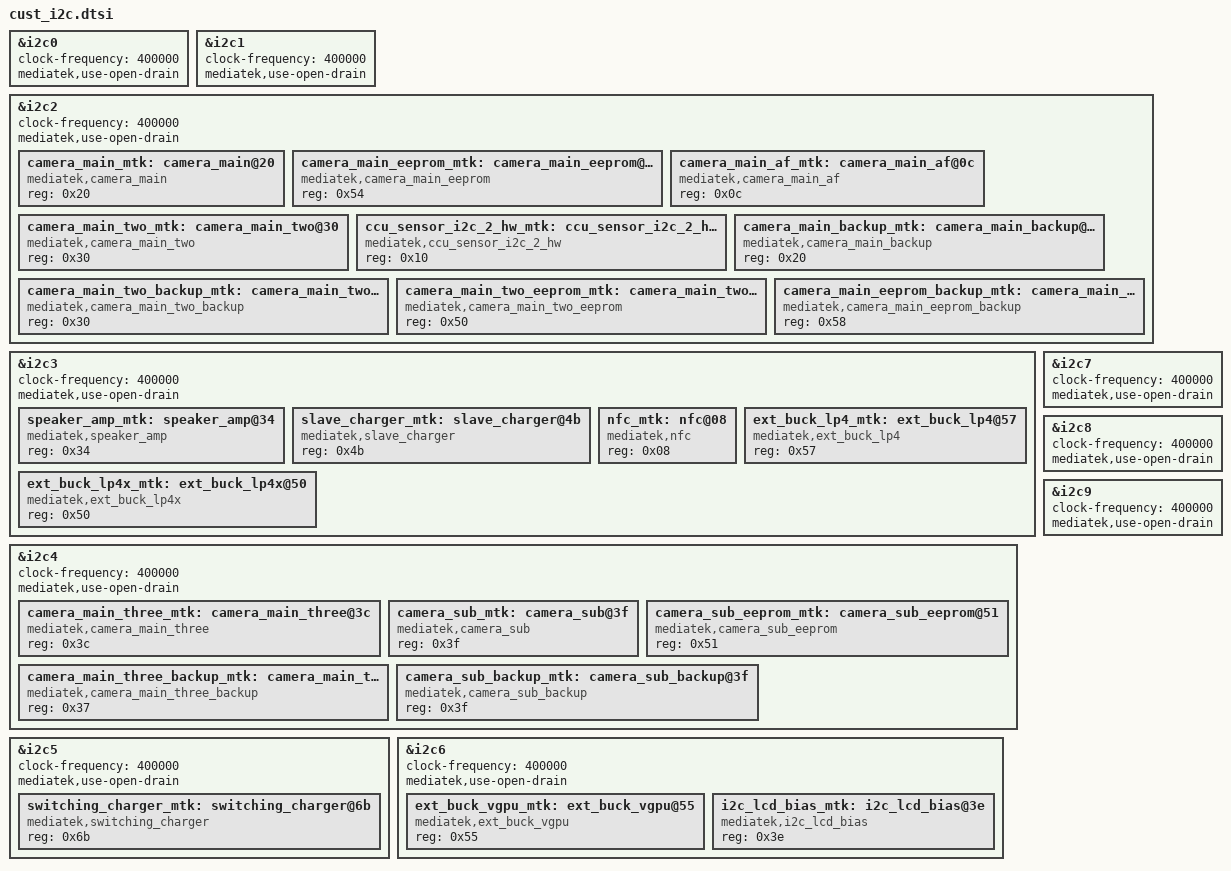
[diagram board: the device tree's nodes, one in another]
/*
 * Generated by MTK SP DrvGen Version: 3.5.160809 for MT6765.
 * 2023-08-23 20:59:31
 * Do Not Modify The File.
 * Copyright Mediatek Inc. (c) 2016.
*/

/*************************
 * I2C DTSI File
*************************/

&i2c0 {
	#address-cells = <1>;
	#size-cells = <0>;
	clock-frequency = <400000>;
	mediatek,use-open-drain;
};

&i2c1 {
	#address-cells = <1>;
	#size-cells = <0>;
	clock-frequency = <400000>;
	mediatek,use-open-drain;
};

&i2c2 {
	#address-cells = <1>;
	#size-cells = <0>;
	clock-frequency = <400000>;
	mediatek,use-open-drain;
	camera_main_mtk:camera_main@20 {
		compatible = "mediatek,camera_main";
		reg = <0x20>;
		status = "okay";
	};

	camera_main_eeprom_mtk:camera_main_eeprom@54 {
		compatible = "mediatek,camera_main_eeprom";
		reg = <0x54>;
		status = "okay";
	};

	camera_main_af_mtk:camera_main_af@0c {
		compatible = "mediatek,camera_main_af";
		reg = <0x0c>;
		status = "okay";
	};

	camera_main_two_mtk:camera_main_two@30 {
		compatible = "mediatek,camera_main_two";
		reg = <0x30>;
		status = "okay";
	};

	ccu_sensor_i2c_2_hw_mtk:ccu_sensor_i2c_2_hw@10 {
		compatible = "mediatek,ccu_sensor_i2c_2_hw";
		reg = <0x10>;
		status = "okay";
	};

	camera_main_backup_mtk:camera_main_backup@20 {
		compatible = "mediatek,camera_main_backup";
		reg = <0x20>;
		status = "okay";
	};

	camera_main_two_backup_mtk:camera_main_two_backup@30 {
		compatible = "mediatek,camera_main_two_backup";
		reg = <0x30>;
		status = "okay";
	};

	camera_main_two_eeprom_mtk:camera_main_two_eeprom@50 {
		compatible = "mediatek,camera_main_two_eeprom";
		reg = <0x50>;
		status = "okay";
	};

	camera_main_eeprom_backup_mtk:camera_main_eeprom_backup@58 {
		compatible = "mediatek,camera_main_eeprom_backup";
		reg = <0x58>;
		status = "okay";
	};

};

&i2c3 {
	#address-cells = <1>;
	#size-cells = <0>;
	clock-frequency = <400000>;
	mediatek,use-open-drain;
	speaker_amp_mtk:speaker_amp@34 {
		compatible = "mediatek,speaker_amp";
		reg = <0x34>;
		status = "okay";
	};

	slave_charger_mtk:slave_charger@4b {
		compatible = "mediatek,slave_charger";
		reg = <0x4b>;
		status = "okay";
	};

	nfc_mtk:nfc@08 {
		compatible = "mediatek,nfc";
		reg = <0x08>;
		status = "okay";
	};

	ext_buck_lp4_mtk:ext_buck_lp4@57 {
		compatible = "mediatek,ext_buck_lp4";
		reg = <0x57>;
		status = "okay";
	};

	ext_buck_lp4x_mtk:ext_buck_lp4x@50 {
		compatible = "mediatek,ext_buck_lp4x";
		reg = <0x50>;
		status = "okay";
	};

};

&i2c4 {
	#address-cells = <1>;
	#size-cells = <0>;
	clock-frequency = <400000>;
	mediatek,use-open-drain;
	camera_main_three_mtk:camera_main_three@3c {
		compatible = "mediatek,camera_main_three";
		reg = <0x3c>;
		status = "okay";
	};

	camera_sub_mtk:camera_sub@3f {
		compatible = "mediatek,camera_sub";
		reg = <0x3f>;
		status = "okay";
	};

	camera_sub_eeprom_mtk:camera_sub_eeprom@51 {
		compatible = "mediatek,camera_sub_eeprom";
		reg = <0x51>;
		status = "okay";
	};

	camera_main_three_backup_mtk:camera_main_three_backup@37 {
		compatible = "mediatek,camera_main_three_backup";
		reg = <0x37>;
		status = "okay";
	};

	camera_sub_backup_mtk:camera_sub_backup@3f {
		compatible = "mediatek,camera_sub_backup";
		reg = <0x3f>;
		status = "okay";
	};

};

&i2c5 {
	#address-cells = <1>;
	#size-cells = <0>;
	clock-frequency = <400000>;
	mediatek,use-open-drain;
	switching_charger_mtk:switching_charger@6b {
		compatible = "mediatek,switching_charger";
		reg = <0x6b>;
		status = "okay";
	};

};

&i2c6 {
	#address-cells = <1>;
	#size-cells = <0>;
	clock-frequency = <400000>;
	mediatek,use-open-drain;
	ext_buck_vgpu_mtk:ext_buck_vgpu@55 {
		compatible = "mediatek,ext_buck_vgpu";
		reg = <0x55>;
		status = "okay";
	};

	i2c_lcd_bias_mtk:i2c_lcd_bias@3e {
		compatible = "mediatek,i2c_lcd_bias";
		reg = <0x3e>;
		status = "okay";
	};

};

&i2c7 {
	#address-cells = <1>;
	#size-cells = <0>;
	clock-frequency = <400000>;
	mediatek,use-open-drain;
};

&i2c8 {
	#address-cells = <1>;
	#size-cells = <0>;
	clock-frequency = <400000>;
	mediatek,use-open-drain;
};

&i2c9 {
	#address-cells = <1>;
	#size-cells = <0>;
	clock-frequency = <400000>;
	mediatek,use-open-drain;
};

